# SN32F780 register map
Vendor: SONiX Technology Co., Ltd.; Series: SN32F780; File version: 0.75
CPU: CM0 r0p0, little endian, no MPU, no FPU, 2 interrupt priority bits
Registers are 32-bit, read-write, reset 0x0 unless marked. A register's access mark holds for its fields unless they carry their own. Offsets are from the block's base; [hi:lo] are bit positions; {n}, {i} and the like mark numbered series.

## SN_ADC — ADC
Base 0x40026000
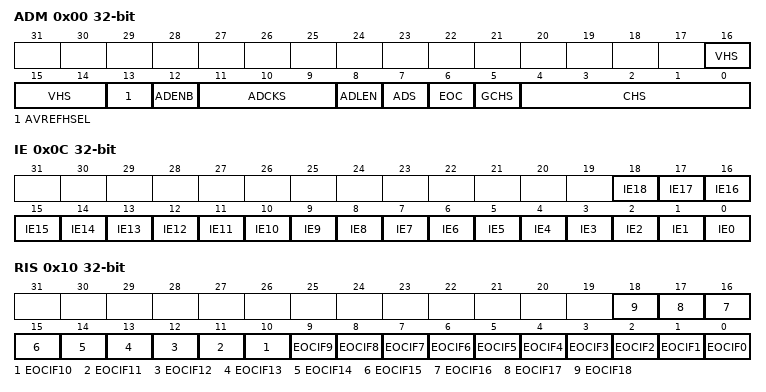
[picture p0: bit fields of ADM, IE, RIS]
0x00 ADM — Offset:0x00 ADC Management Register
  [16:14] VHS — Internal Ref. voltage source
    0=000b (Internal 2.0V as ADC internal reference high voltage); 1=001b (Internal 3.0V as ADC internal reference high voltage); 2=010b (Internal 4.5V as ADC internal reference high voltage); 4=100b (VDD as ADC internal reference high voltage, Internal 2.0V as AIN10); 5=101b (VDD as ADC internal reference high voltage, Internal 3.0V as AIN10); 6=110b (VDD as ADC internal reference high voltage, Internal 4.5V as AIN10); 7=111b (VDD as ADC internal reference high voltage)
  [13] AVREFHSEL — ADC high reference voltage source
    0=Interal VDD (P2.0 acts as GPIO or AIN0 pin); 1=External reference voltage (P2.0 acts as AVREFH pin)
  [12] ADENB — ADC enable
    0=Disable ADC; 1=Enable ADC
  [11:9] ADCKS — ADC clock source divider
    0=000b (ADC_PCLK/1); 1=001b (ADC_PCLK/2); 2=010b (ADC_PCLK/4); 3=011b (ADC_PCLK/8); 5=101b (ADC_PCLK/16); 6=110b (ADC_PCLK/32)
  [8] ADLEN — ADC resolution
    0=8-bit ADB; 1=12-bit ADB
  [7] ADS — ADC start control
    0=Stop (ADC stopped); 1=Start ADC conversion
  [6] EOC — ADC status
    0=Busy (ADC processing); 1=End (End of conversion)
  [5] GCHS — ADC global channel enable
    0=Disable AIN channel; 1=Enable AIN channel
  [4:0] CHS — ADC input channel
    {v}=AIN{v} (v=0..15); 16=AIN16(Internal reference voltage 4.5V/3V/2V); 17=AIN17(OP0O); 18=AIN18(OP1O)
0x04 ADB ro — Offset:0x04 ADC Data Register
  [11:0] ADB — ADB11~ADB4 bits for 8-bit ADC, ADB11~ADB0 bits for 12-bit ADC
0x0C IE — Offset:0x0C ADC Interrupt Enable Register
  [n] IE{n} (n=0..18) — AIN{n} interrupt enable
    0=Disable AIN{n} interrupt; 1=Enable (ADC interrupt is triggered when AIN{n} completes ADC conversion)
0x10 RIS — Offset:0x10 ADC Raw Interrupt Status Register
  [n] EOCIF{n} (n=4..18) — AIN{n} interrupt flag
    0=No interrupt on AIN{n}; 1=Met interrupt requirements (AIN{n} completes ADC conversion)
  [3] EOCIF3 — AIN0 interrupt flag
    0=No interrupt on AIN3; 1=Met interrupt requirements (AIN3 completes ADC conversion)
  [2] EOCIF2 — AIN2 interrupt flag
    0=No interrupt on AIN2; 1=Met interrupt requirements (AIN2 completes ADC conversion)
  [1] EOCIF1 — AIN1 interrupt flag
    0=No interrupt on AIN1; 1=Met interrupt requirements (AIN1 completes ADC conversion)
  [0] EOCIF0 — AIN0 interrupt flag
    0=No interrupt on AIN0; 1=Met interrupt requirements (AIN0 completes ADC conversion)
0x14 CALI (reset mask 0xDF) — Offset:0x14 ADC Calibration Register

## SN_WDT — Watchdog Timer
Base 0x40010000
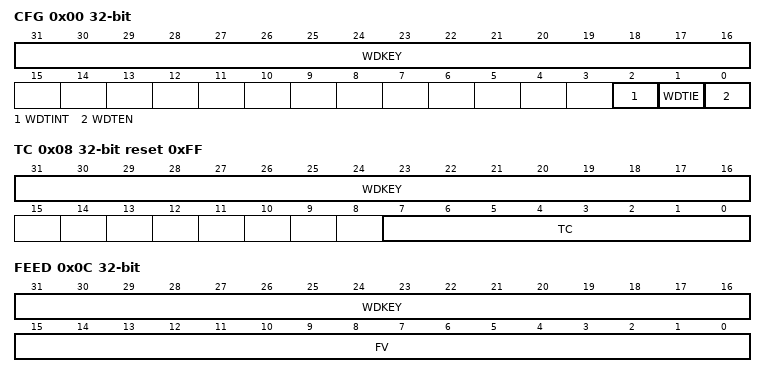
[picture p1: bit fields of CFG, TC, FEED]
0x00 CFG — Offset:0x00 WDT Configuration Register
  [31:16] WDKEY wo — WDT register key
  [2] WDTINT — WDT interrupt flag
    0=No (No WDT time-out); 1=WDT time-out (WDT interrupt is triggered if WDTIE=1)
  [1] WDTIE — WDT interrupt enable
    0=Disable (WDT reset when WDT time-out); 1=Enable WDT interrupt
  [0] WDTEN — WDT enable
    0=Disable WDT; 1=Enable WDT
0x08 TC reset 0xFF — Offset:0x08 WDT Timer Constant Register
  [31:16] WDKEY wo — WDT register key
  [7:0] TC — Watchdog timer constant reload value
0x0C FEED wo — Offset:0x0C WDT Feed Register
  [31:16] WDKEY — WDT register key
  [15:0] FV — Watchdog feed value

## SN_RTC — Real-time Clock
Base 0x40012000
0x00 CTRL — Offset:0x00 RTC Control Register
  [0] RTCEN — RTC enable
    0=Disable RTC; 1=Enable RTC
0x04 CLKS — Offset:0x04 RTC Clock Source Register
  [0] CLKSEL — RTC clock source
    0=ILRC (RTC clock source=ILRC); 1=ELS XTAL (RTC clock source=ELS XTAL)
0x08 IE — Offset:0x08 RTC Interrupt Enable Register
  [0] SECIE — Second interrupt enable
    0=Disable second interrupt; 1=Enable second interrupt
0x0C RIS ro — Offset:0x0C RTC Raw Interrupt Status Register
  [0] SECIF — Second interrupt flag
    0=No (No second interrupt); 1=Met (Second interrupt is triggered when SECIE=1)
0x10 IC wo — Offset:0x10 RTC Interrupt Clear Register
  [0] SECIC — Second interrupt flag clear
    0=No effect; 1=Clear second interrupt flag
0x14 SECCNTV reset 0x8000 (reset mask 0xFFFFF) — Offset:0x14 RTC Second Counter Reload Value Register
0x18 SECCNT ro — Offset:0x18 RTC Second Counter Register
